# STM32G534 register map
File version: 2.0.0
CPU: CM33 r0p4, little endian, MPU, FPU, 4 interrupt priority bits
Registers are 32-bit, read-write, reset 0x0 unless marked. A register's access mark holds for its fields unless they carry their own. Offsets are from the block's base; [hi:lo] are bit positions; {n}, {i} and the like mark numbered series; 'fields as' and 'values as' point back to an identical list.

## RAMCFG — RAMCFG address block description
Base 0x40026000
Same registers: RAMCFG_S 0x50026000
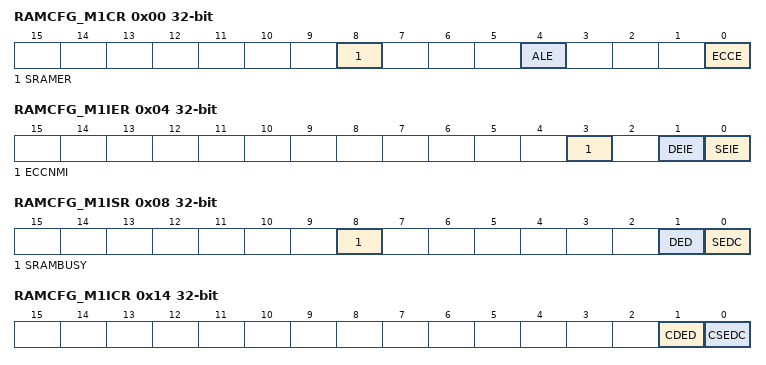
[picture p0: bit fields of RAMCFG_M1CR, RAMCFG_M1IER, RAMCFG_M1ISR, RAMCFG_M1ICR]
0x00 RAMCFG_M1CR (reset mask 0xFFFFFFF0) — RAMCFG memory 1 control register
  [8] SRAMER — SRAM erase
    0=No erase operation on going; 1=Erase operation on going
  [4] ALE — Address latch enable
    0=Failing address not stored in the SRAMx ECC single/double error address registers; 1=Failing address stored in the SRAMx ECC single/double error address registers
  [0] ECCE — ECC enable.
    0=ECC disabled; 1=ECC enabled
0x04 RAMCFG_M1IER — RAMCFG memory 1 interrupt enable register
  [3] ECCNMI — Double error NMI
    0=NMI not generated in case of ECC double error; 1=NMI generated in case of ECC double error
  [1] DEIE — ECC double error interrupt enable
    0=Double error interrupt disabled; 1=Double error interrupt enabled
  [0] SEIE — ECC single error interrupt enable
    0=Single error interrupt disabled; 1=Single error interrupt enabled
0x08 RAMCFG_M1ISR ro — RAMCFG memory interrupt status register
  [8] SRAMBUSY — SRAM busy with erase operation
    0=No erase operation on going; 1=Erase operation on going
  [1] DED — ECC double error detected
    0=No double error; 1=Double error detected
  [0] SEDC — ECC single error detected and corrected
    0=No single error; 1=Single error detected and corrected
0x0C RAMCFG_M1SEAR ro — RAMCFG memory 1 ECC single error address register
  [31:0] ESEA — ECC single error address
0x10 RAMCFG_M1DEAR ro — RAMCFG memory 1 ECC double error address register
  [31:0] EDEA — ECC double error address
0x14 RAMCFG_M1ICR — RAMCFG memory 1 interrupt clear register 1
  [1] CDED — Clear ECC double error detected
  [0] CSEDC — Clear ECC single error detected and corrected
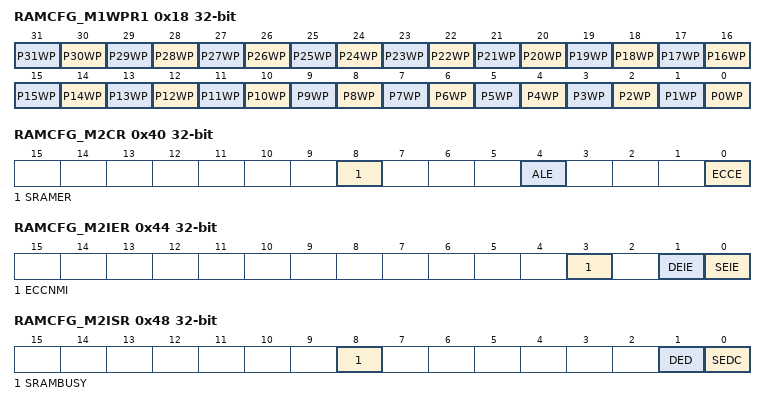
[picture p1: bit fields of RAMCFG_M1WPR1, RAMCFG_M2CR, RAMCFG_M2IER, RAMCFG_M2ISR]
0x18 RAMCFG_M1WPR1 — RAMCFG memory 2 write protection register 1
  [all] fields
    0=Write protection of SRAMx 1-Kbyte page y is disabled; 1=Write protection of SRAMx 1-Kbyte page y is enabled
  [n] P{n}WP (n=0..31) — SRAM2 1-Kbyte page y write protection
0x24 RAMCFG_M1ECCKEYR wo — RAMCFG memory 1 ECC key register
  [7:0] ECCKEY — ECC write protection key
0x28 RAMCFG_M1ERKEYR wo — RAMCFG memory 1 erase key register
  [7:0] ERASEKEY — Erase write protection key
0x40 RAMCFG_M2CR (reset mask 0xFFFFFFF0) — RAMCFG memory 2 control register
  fields as RAMCFG_M1CR
0x44 RAMCFG_M2IER — RAMCFG memory 2 interrupt enable register
  fields as RAMCFG_M1IER
0x48 RAMCFG_M2ISR ro — RAMCFG memory interrupt status register
  fields as RAMCFG_M1ISR
0x4C RAMCFG_M2SEAR ro — RAMCFG memory 2 ECC single error address register
  [31:0] ESEA — ECC single error address
0x50 RAMCFG_M2DEAR ro — RAMCFG memory 2 ECC double error address register
  [31:0] EDEA — ECC double error address
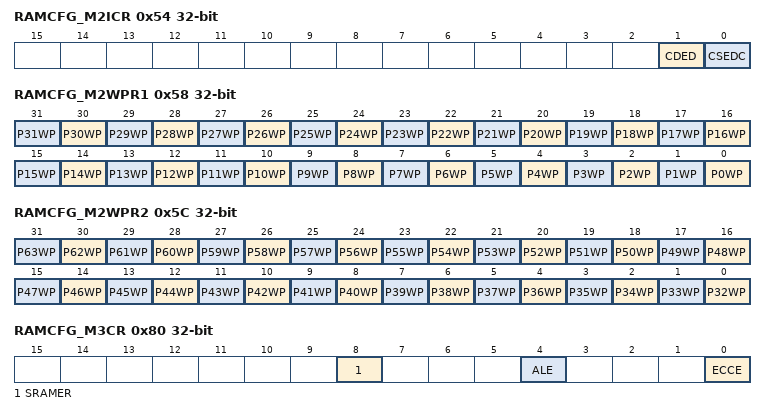
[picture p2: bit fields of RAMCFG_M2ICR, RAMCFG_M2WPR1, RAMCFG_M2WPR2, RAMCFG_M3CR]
0x54 RAMCFG_M2ICR — RAMCFG memory 2 interrupt clear register 2
  fields as RAMCFG_M1ICR
0x58 RAMCFG_M2WPR1 — RAMCFG memory 2 write protection register 1
  fields as RAMCFG_M1WPR1
0x5C RAMCFG_M2WPR2 — RAMCFG memory 2 write protection register 2
  [all] fields
    0=Write protection of SRAM2 1-Kbyte page y is disabled; 1=Write protection of SRAM2 1-Kbyte page y is enabled
  [n-32] P{n}WP (n=32..63) — SRAM2 1-Kbyte page y write protection
0x64 RAMCFG_M2ECCKEYR wo — RAMCFG memory 2 ECC key register
  [7:0] ECCKEY — ECC write protection key
0x68 RAMCFG_M2ERKEYR wo — RAMCFG memory 2 erase key register
  [7:0] ERASEKEY — Erase write protection key
0x80 RAMCFG_M3CR (reset mask 0xFFFFFFF0) — RAMCFG memory 3 control register
  fields as RAMCFG_M1CR
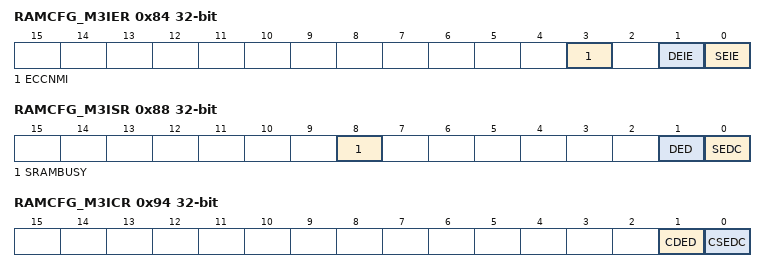
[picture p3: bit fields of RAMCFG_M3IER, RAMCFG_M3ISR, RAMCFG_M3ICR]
0x84 RAMCFG_M3IER — RAMCFG memory 3 interrupt enable register
  fields as RAMCFG_M1IER
0x88 RAMCFG_M3ISR ro — RAMCFG memory interrupt status register
  fields as RAMCFG_M1ISR
0x8C RAMCFG_M3SEAR ro — RAMCFG memory 3 ECC single error address register
  [31:0] ESEA — ECC single error address
0x90 RAMCFG_M3DEAR ro — RAMCFG memory 3 ECC double error address register
  [31:0] EDEA — ECC double error address
0x94 RAMCFG_M3ICR — RAMCFG memory 3 interrupt clear register 3
  fields as RAMCFG_M1ICR
0xA4 RAMCFG_M3ECCKEYR wo — RAMCFG memory 3 ECC key register
  [7:0] ECCKEY — ECC write protection key
0xA8 RAMCFG_M3ERKEYR wo — RAMCFG memory 3 erase key register
  [7:0] ERASEKEY — Erase write protection key
